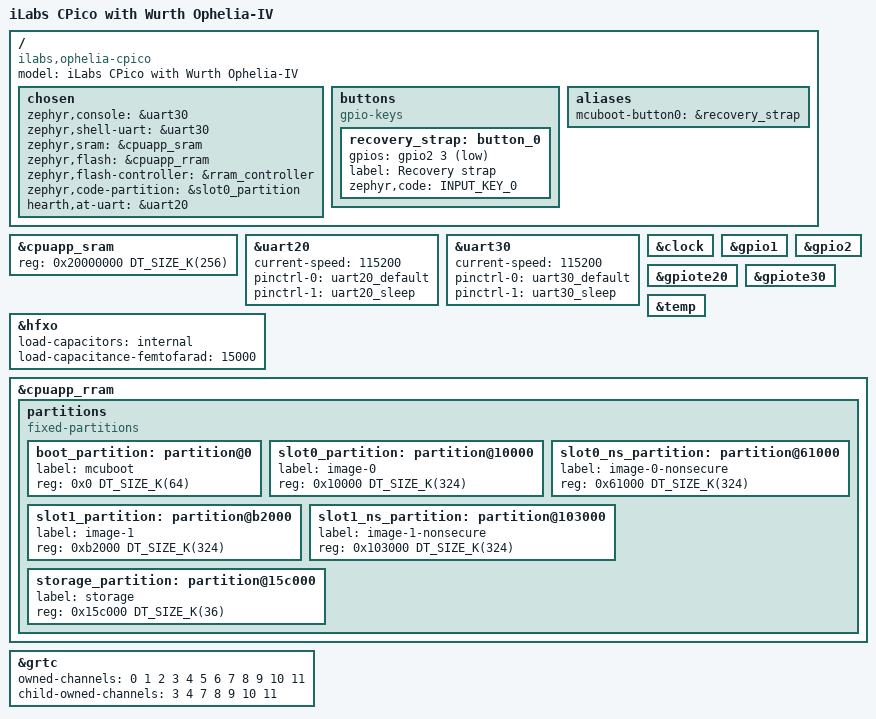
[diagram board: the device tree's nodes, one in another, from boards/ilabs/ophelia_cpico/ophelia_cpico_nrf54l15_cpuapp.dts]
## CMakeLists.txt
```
cmake_minimum_required(VERSION 3.20.0)
list(APPEND BOARD_ROOT ${CMAKE_CURRENT_LIST_DIR})
find_package(Zephyr REQUIRED HINTS $ENV{ZEPHYR_BASE})
project(hearth_nrf54l15)

# ---- the board contract (README.md, "Adding a board") -------------------
#
# A board on this platform has to name a UART twice, and it has to be the
# same UART both times:
#
#   the application's  hearth,at-uart      chosen node: where AT is spoken
#   MCUboot's          zephyr,uart-mcumgr  chosen node: where serial
#                                          recovery answers
#
# fw/flash.py drives ONE port and needs both of them. It straps the module
# into recovery, uploads the signed image over SMP, releases the strap and
# then waits for the application's +MTREADY, all on the same wire, because
# one wire is what a carrier brings out. A board whose two answers differ is
# not reflashable over that wire at all, and on a module whose SWD pads are a
# soldering job, that is a brick rather than an inconvenience.
#
# The two facts live in two images with two devicetrees, so no static_assert
# and no devicetree macro can see both. This checks the INPUT instead: it
# finds MCUboot's per-board overlay in this tree with the same zephyr_file()
# lookup MCUboot itself will use, reads the node label it names, and resolves
# that label against THIS image's devicetree. It catches the failure the
# round it was written for existed to remove (uart20 pinned unconditionally
# for every board, right on ophelia_cpico and the CONSOLE on both Nordic
# DKs, with nothing in the build saying so). It does not catch a
# -Dmcuboot_DTC_OVERLAY_FILE=... on the command line, which goes around the
# lookup entirely. That is the honest limit of a cross-image check here, and
# it is still worth having, because the version of this failure that has no
# check is silent until a board is on the bench.
string(REPLACE "/" "_" HEARTH_BOARD_FILE "${BOARD}${BOARD_QUALIFIERS}")

dt_chosen(HEARTH_AT_UART_NODE PROPERTY "hearth,at-uart")
if(NOT HEARTH_AT_UART_NODE)
  message(FATAL_ERROR
    "Board ${BOARD}${BOARD_QUALIFIERS} declares no `hearth,at-uart` chosen "
    "node, so nothing in this build says which UART carries the AT link.\n"
    "Add it to the board's devicetree, either a board directory under\n"
    "  ${CMAKE_CURRENT_LIST_DIR}/boards/<vendor>/<board>/\n"
    "for a board this repository defines, or an application overlay at\n"
    "  ${CMAKE_CURRENT_LIST_DIR}/boards/${HEARTH_BOARD_FILE}.overlay\n"
    "for an upstream board:\n"
    "  / { chosen { hearth,at-uart = &uartNN; }; };\n"
    "  &uartNN { status = \"okay\"; current-speed = <115200>; };\n"
    "There is deliberately no default. uart20 is the AT link on "
    "ophelia_cpico and is the CONSOLE on both Nordic DKs, so a default would "
    "be a coin toss that answers AT on the wrong pins without failing.\n"
    "See platform/nrf54l15/README.md, \"Adding a board\".")
endif()

if(CONFIG_BOOTLOADER_MCUBOOT)
  # The same two directories, in the same order, that MCUboot's own
  # DTC_OVERLAY_FILE discovery reads under its APPLICATION_CONFIG_DIR
  # (configuration_files.cmake:70-72: socs first, then boards), with the
  # SUFFIX every Zephyr-side lookup passes. Later entries win in devicetree
  # application order, and the loop below keeps the last match, so the two
  # agree about which file decides.
  set(HEARTH_MCUBOOT_IMAGE_DIR ${CMAKE_CURRENT_LIST_DIR}/sysbuild/mcuboot)
  set(HEARTH_MCUBOOT_BOARDS_DIR ${HEARTH_MCUBOOT_IMAGE_DIR}/boards)
  set(HEARTH_MCUBOOT_OVERLAYS)
  zephyr_file(CONF_FILES ${HEARTH_MCUBOOT_IMAGE_DIR}/socs DTS HEARTH_MCUBOOT_OVERLAYS
              QUALIFIERS SUFFIX ${FILE_SUFFIX})
  zephyr_file(CONF_FILES ${HEARTH_MCUBOOT_BOARDS_DIR} DTS HEARTH_MCUBOOT_OVERLAYS
              SUFFIX ${FILE_SUFFIX})

  set(HEARTH_MCUMGR_LABEL)
  set(HEARTH_MCUMGR_FILE)
  foreach(overlay ${HEARTH_MCUBOOT_OVERLAYS})
    file(READ ${overlay} hearth_overlay_text)
    # Comments come out first. CMake's MATCHES returns the FIRST match in the
    # string and these files are comment-heavy by house style, so a header
    # that quotes the property name in prose would otherwise steer the check
    # at whatever label the prose mentioned, and steer it SILENTLY, which is
    # the one failure class this whole check exists to remove.
    string(REGEX REPLACE "/\\*[^*]*\\*+([^/*][^*]*\\*+)*/" "" hearth_overlay_text
           "${hearth_overlay_text}")
    string(REGEX REPLACE "//[^\n]*" "" hearth_overlay_text "${hearth_overlay_text}")
    # `[^&]*` cannot cross the ampersand it is looking for, so this matches
    # the label of the first phandle after the property name and nothing
    # further. Whitespace and line breaks between the two are free. A value
    # written as a path phandle, &{/soc/uart@c6000}, matches nothing and
    # falls through to the "no zephyr,uart-mcumgr" error below, which still
    # points at the right file.
    if(hearth_overlay_text MATCHES "zephyr,uart-mcumgr[^&]*&([A-Za-z0-9_]+)")
      set(HEARTH_MCUMGR_LABEL ${CMAKE_MATCH_1})
      set(HEARTH_MCUMGR_FILE ${overlay})
    endif()
    unset(hearth_overlay_text)
  endforeach()

  if(NOT HEARTH_MCUMGR_LABEL)
    message(FATAL_ERROR
      "Board ${BOARD}${BOARD_QUALIFIERS} has no MCUboot serial-recovery UART.\n"
      "Nothing under\n"
      "  ${HEARTH_MCUBOOT_BOARDS_DIR}/\n"
      "sets `zephyr,uart-mcumgr` for this board; the file this build looks "
      "for is\n"
      "  ${HEARTH_MCUBOOT_BOARDS_DIR}/${HEARTH_BOARD_FILE}.overlay\n"
      "(a socs/ overlay for this SoC would do as well, and is read first)\n"
      "and it must name the same node as this board's `hearth,at-uart`, "
      "which is ${HEARTH_AT_UART_NODE}:\n"
      "  / { chosen { zephyr,uart-mcumgr = &uartNN; }; };\n"
      "  &uartNN { status = \"okay\"; };\n"
      "(Files found for this board: ${HEARTH_MCUBOOT_OVERLAYS})\n"
      "See platform/nrf54l15/README.md, \"Adding a board\".")
  endif()

  dt_nodelabel(HEARTH_MCUMGR_NODE NODELABEL "${HEARTH_MCUMGR_LABEL}")
  if(NOT HEARTH_MCUMGR_NODE)
    message(FATAL_ERROR
      "${HEARTH_MCUMGR_FILE}\n"
      "sets `zephyr,uart-mcumgr = &${HEARTH_MCUMGR_LABEL};`, but no node "
      "labelled ${HEARTH_MCUMGR_LABEL} exists in this board's devicetree. "
      "The two images share the board, so a label MCUboot can resolve is a "
      "label this image can resolve. Either the spelling is wrong, or the "
      "label is one the MCUboot overlay defines itself, which the AT link "
      "cannot be on: it has to be a node this image has too.")
  endif()

  if(NOT HEARTH_MCUMGR_NODE STREQUAL HEARTH_AT_UART_NODE)
    message(FATAL_ERROR
      "The AT link and MCUboot's serial recovery are on different UARTs on "
      "board ${BOARD}${BOARD_QUALIFIERS}, and fw/flash.py drives one port:\n"
      "  hearth,at-uart      ${HEARTH_AT_UART_NODE}\n"
      "  zephyr,uart-mcumgr  ${HEARTH_MCUMGR_NODE} (&${HEARTH_MCUMGR_LABEL})\n"
      "                      set in ${HEARTH_MCUMGR_FILE}\n"
      "Recovery would answer on a port the flasher never opens. Change "
      "whichever of the two is wrong for the hardware; on a carrier that "
      "brings out one UART, the AT link is the fixed point and recovery "
      "follows it.\n"
      "See platform/nrf54l15/README.md, \"Adding a board\".")
  endif()

  # ---- what the sysbuild/mcuboot/ directory costs, and its guard --------
  #
  # Creating that directory is what makes boards/<board>.overlay work for
  # the MCUboot image, and it is not free: sysbuild redirects the image's
  # APPLICATION_CONFIG_DIR to it (sysbuild_extensions.cmake, the
  # sysbuild_image_name_conf_dir branch), so Zephyr stops looking in
  # MCUboot's own bootloader/mcuboot/boot/zephyr for the image's
  # configuration inputs and looks here instead. Upstream ships three
  # Kconfig inputs at the paths that move:
  #
  #   prj.conf                    MCUboot's own base configuration
  #   socs/<soc>_<cluster>.conf   the per-SoC fragment
  #   boards/<board>.conf         a per-board fragment, if upstream has one
  #
  # Missing prj.conf fails the configure outright, which is at least loud.
  # A missing SoC fragment is SILENT: on the nRF54L15 it costs LTO,
  # ISR_TABLES_LOCAL_DECLARATION, the 512-byte RRAM write buffer
  # (NRF_RRAM_WRITE_BUFFER_SIZE counts 128-bit words, so 32 is 512 bytes and
  # the fallback 1 is 16) and BOOT_WATCHDOG_FEED=n, and the bootloader still
  # builds and still boots. So the two that exist for these SoCs are copied
  # under sysbuild/mcuboot/ (each file says so in its header) and this asks
  # upstream what it WOULD have contributed for the board being built, then
  # requires each answer to appear verbatim in the copy. An NCS bump that
  # edits one of them, and a new board whose SoC fragment nobody copied,
  # both fail here with the file to copy named. Same shape as the SDK patch
  # gate below: check the thing the build otherwise cannot see.
  #
  # THE REDIRECT MOVES THE DEVICETREE LOOKUPS TOO, and this guard does not
  # cover them, deliberately. Upstream also ships boot/zephyr/app.overlay,
  # boot/zephyr/boards/*.overlay and boot/zephyr/socs/*.overlay, and the
  # same APPLICATION_CONFIG_DIR redirect moves where those are looked for
  # (configuration_files.cmake:70-83). Nothing was lost there, because they
  # were already not applied before this round: sysbuild/mcuboot.overlay set
  # mcuboot_DTC_OVERLAY_FILE, which makes DTC_OVERLAY_FILE defined and skips
  # all three lookups outright. Demanding copies would therefore not restore
  # a lost setting, it would APPLY one for the first time: carrying
  # app.overlay would put zephyr,code-partition on &boot_partition where
  # this bootloader's devicetree has taken it from the board .dts since the
  # image existed, which Partition Manager overrides anyway. So the rule for
  # a new board is a reading task rather than a check: look in
  # bootloader/mcuboot/boot/zephyr/{boards,socs}/ for your target and fold
  # anything you need into your own per-board overlay by hand, because it
  # will not arrive on its own. README.md, "Adding a board", says so too.
  #
  # For the record on who does what upstream, because the first version of
  # this comment got it wrong: Nordic's Matter samples do NOT copy this
  # prj.conf. They author a bespoke, size-trimmed one and re-add LTO and
  # ISR_TABLES_LOCAL_DECLARATION in it and BOOT_WATCHDOG_FEED=n in their
  # per-board .conf, losing only NRF_RRAM_WRITE_BUFFER_SIZE. The copy-and-
  # carry-socs pattern used here is the one the SDK's own DFU samples use
  # (samples/dfu/compressed_update, samples/bluetooth/mesh/dfu/{target,
  # distributor}), so this is the SDK's other convention, not a departure
  # from it.
  if(NOT DEFINED ZEPHYR_MCUBOOT_MODULE_DIR)
    message(FATAL_ERROR
      "CONFIG_BOOTLOADER_MCUBOOT is set but the mcuboot Zephyr module is not "
      "in this workspace, so the bootloader image's configuration cannot be "
      "checked against upstream's.")
  endif()
  set(HEARTH_MCUBOOT_UPSTREAM_DIR ${ZEPHYR_MCUBOOT_MODULE_DIR}/boot/zephyr)
  set(HEARTH_MCUBOOT_LOCAL_DIR ${CMAKE_CURRENT_LIST_DIR}/sysbuild/mcuboot)

  # prj.conf is named rather than discovered, so unlike every other entry in
  # this list it is not known to exist. An upstream that ever drops it would
  # otherwise reach file(READ) and give a raw CMake error instead of this
  # block's own message.
  set(HEARTH_MCUBOOT_UPSTREAM_CONFS)
  if(EXISTS ${HEARTH_MCUBOOT_UPSTREAM_DIR}/prj.conf)
    list(APPEND HEARTH_MCUBOOT_UPSTREAM_CONFS ${HEARTH_MCUBOOT_UPSTREAM_DIR}/prj.conf)
  else()
    message(FATAL_ERROR
      "MCUboot no longer ships boot/zephyr/prj.conf, which this platform's "
      "sysbuild/mcuboot/prj.conf is a copy of:\n"
      "  looked for: ${HEARTH_MCUBOOT_UPSTREAM_DIR}/prj.conf\n"
      "Re-read how the MCUboot image gets its base configuration in this NCS "
      "before trusting the copy.")
  endif()
  zephyr_file(CONF_FILES ${HEARTH_MCUBOOT_UPSTREAM_DIR}/socs
              KCONF HEARTH_MCUBOOT_UPSTREAM_CONFS QUALIFIERS SUFFIX ${FILE_SUFFIX})
  zephyr_file(CONF_FILES ${HEARTH_MCUBOOT_UPSTREAM_DIR}/boards
              KCONF HEARTH_MCUBOOT_UPSTREAM_CONFS SUFFIX ${FILE_SUFFIX})

  # Containment, not equality, because the copies carry a header comment.
  # The consequence, stated here and in the copies: this sees upstream
  # changing, and does not see lines ADDED to a copy below the verbatim
  # block. Those apply silently and are the copies' one soft edge.
  foreach(upstream_conf ${HEARTH_MCUBOOT_UPSTREAM_CONFS})
    file(RELATIVE_PATH hearth_conf_rel ${HEARTH_MCUBOOT_UPSTREAM_DIR} ${upstream_conf})
    set(hearth_local_conf ${HEARTH_MCUBOOT_LOCAL_DIR}/${hearth_conf_rel})
    if(NOT EXISTS ${hearth_local_conf})
      message(FATAL_ERROR
        "MCUboot has a Kconfig fragment for board "
        "${BOARD}${BOARD_QUALIFIERS} that this platform does not carry, and "
        "the bootloader image will be built without it:\n"
        "  upstream: ${upstream_conf}\n"
        "  wanted:   ${hearth_local_conf}\n"
        "Copy it, under a header comment saying it is a copy and why (the "
        "files already there show the shape). It is not optional: the "
        "sysbuild/mcuboot/ directory that gives this image its per-board "
        "recovery-UART overlay also redirects where Zephyr looks for these, "
        "so what is not copied is simply not applied.")
    endif()
    file(READ ${upstream_conf} hearth_conf_upstream_text)
    file(READ ${hearth_local_conf} hearth_conf_local_text)
    string(FIND "${hearth_conf_local_text}" "${hearth_conf_upstream_text}"
           hearth_conf_found)
    if(hearth_conf_found EQUAL -1)
      message(FATAL_ERROR
        "MCUboot's own ${hearth_conf_rel} has changed and this platform's "
        "copy of it has not:\n"
        "  upstream: ${upstream_conf}\n"
        "  copy:     ${hearth_local_conf}\n"
        "Put upstream's current content back under the header comment in "
        "the copy, then rebuild the bootloader image and look at what "
        "moved.")
    endif()
    unset(hearth_conf_upstream_text)
    unset(hearth_conf_local_text)
  endforeach()
endif()

include(${CMAKE_CURRENT_LIST_DIR}/../../core/sources.cmake)

target_sources(app PRIVATE
    port/hearth_port_zephyr.c
    ${HEARTH_CORE_SOURCES})
target_include_directories(app PRIVATE ${HEARTH_CORE_INCLUDE_DIRS} port)
target_compile_definitions(app PRIVATE MT_COMBINED_IMAGE=0)

if(CONFIG_CHIP)
  # ---- the SDK patch gate (sdk-patches/README.md) -----------------------
  #
  # This platform carries patches against the pinned NCS workspace, and an
  # unpatched tree must not build quietly. Every patch here is deliberately
  # written to fall back to upstream behaviour when its macro is unset, which
  # is what makes it upstreamable, and is also exactly why a MISSING patch is
  # invisible: the build succeeds, the firmware works, and several kilobytes
  # of RAM come back without a word. That is the trap this check closes, and
  # the reason it is a hard error rather than a warning in a thousand-line
  # log. The remedy is one command and it is printed here.
  #
  # The marker is a REVISION, not a presence flag. Searching for the
  # configuration macro alone would pass on a workspace still carrying an
  # OLDER cut of the same patch: it would configure, build and measure
  # cleanly while running code nobody reviewed, which is the one failure a
  # presence check cannot see. Each patch therefore defines
  # HEARTH_<name>_PATCH_REV and this gate matches the number this tree
  # expects. Bump both together whenever a patch is re-cut.
  set(HEARTH_SDK_PATCH_DIR ${CMAKE_CURRENT_LIST_DIR}/sdk-patches)
  set(HEARTH_EEM_PATCH_REV 2)
  file(READ
    ${ZEPHYR_CONNECTEDHOMEIP_MODULE_DIR}/src/app/clusters/electrical-energy-measurement-server/ElectricalEnergyMeasurementCluster.cpp
    hearth_eem_src)
  string(FIND "${hearth_eem_src}"
    "HEARTH_EEM_POOL_PATCH_REV ${HEARTH_EEM_PATCH_REV}" hearth_eem_patched)
  string(FIND "${hearth_eem_src}" "HEARTH_EEM_POOL_PATCH_REV" hearth_eem_any_rev)
  unset(hearth_eem_src)
  if(hearth_eem_patched EQUAL -1)
    if(hearth_eem_any_rev EQUAL -1)
      set(hearth_eem_state "is NOT patched")
    else()
      set(hearth_eem_state "carries a DIFFERENT revision of the patch than revision ${HEARTH_EEM_PATCH_REV}, which this tree expects")
    endif()
    message(FATAL_ERROR
      "The Matter module at ${ZEPHYR_CONNECTEDHOMEIP_MODULE_DIR} ${hearth_eem_state}.\n"
      "This platform's memory figures and its EEM capacity both assume the patches in\n"
      "  ${HEARTH_SDK_PATCH_DIR}\n"
      "Apply them from the west workspace (run the clean first only if the tree is\n"
      "already patched at another revision):\n"
      "  cd ${ZEPHYR_BASE}/.. \\\n"
      "    && west patch -l ${HEARTH_SDK_PATCH_DIR}/patches.yml \\\n"
      "                  -b ${HEARTH_SDK_PATCH_DIR} clean \\\n"
      "    && west patch -l ${HEARTH_SDK_PATCH_DIR}/patches.yml \\\n"
      "                  -b ${HEARTH_SDK_PATCH_DIR} apply\n"
      "then build again.\n"
      "README.md in that directory says what each patch does, how to tell whether\n"
      "a tree is patched, and how to take it back out.")
  endif()

  include(${ZEPHYR_CONNECTEDHOMEIP_MODULE_DIR}/config/nrfconnect/app/enable-gnu-std.cmake)
  include(${ZEPHYR_CONNECTEDHOMEIP_MODULE_DIR}/src/app/chip_data_model.cmake)
  target_include_directories(matter-data-model PUBLIC ${CMAKE_CURRENT_SOURCE_DIR}/src/default_zap)
  chip_configure_data_model(matter-data-model
    BYPASS_IDL
    GEN_DIR ${CMAKE_CURRENT_SOURCE_DIR}/src/default_zap/zap-generated
    ZAP_FILE ${CMAKE_CURRENT_SOURCE_DIR}/src/default_zap/hearth.zap)

  set(MATTER_COMMON ${ZEPHYR_NRF_MODULE_DIR}/samples/matter/common/src)
  # src/default_zap is the ZAP_FILE's parent dir (chip_configure_data_model
  # above put the codegen output at src/default_zap/zap-generated): app's own
  # sources (main.cpp, matter_init.cpp) include <zap-generated/gen_config.h>
  # via app/util/attribute-storage.h, and that codegen dir was only ever added
  # to the matter-data-model target's own include path, not app's; mirrors
  # ZAP_PARENT_DIR in the template sample's CMakeLists.txt.
  # ../chip is the +MTEVT mapping shared with the MGM240P arm
  # (platform/chip/mt_chip_events.{h,cpp}). It sits outside this platform
  # directory on purpose: it names stock CHIP symbols only, so both Thread
  # ports compile the same file and the two arms cannot drift apart. It is
  # inside the CONFIG_CHIP guard because that is the only configuration in
  # which those symbols exist.
  target_include_directories(app PRIVATE src src/default_zap ../chip ${MATTER_COMMON}
    ${CMAKE_CURRENT_LIST_DIR}/../common)
  target_sources(app PRIVATE
    src/main.cpp
    ../chip/mt_chip_events.cpp
    port/mt_matter_stub.c
    port/hearth_ota_nrf.cpp
    ${CMAKE_CURRENT_LIST_DIR}/../common/hearth_ota_requestor.cpp
    port/mt_matter_zephyr.cpp
    port/mt_devtypes_zephyr.cpp
    ${MATTER_COMMON}/app/matter_init.cpp
    ${MATTER_COMMON}/app/matter_event_handler.cpp
    ${MATTER_COMMON}/app/task_executor.cpp
    ${MATTER_COMMON}/clusters/cluster_init.cpp)
  zephyr_linker_sources(SECTIONS ${MATTER_COMMON}/clusters/cluster_init.ld)
endif()
```

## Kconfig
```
#
# Without this file, Zephyr auto-generates a trivial app Kconfig root
# (mainmenu + source "Kconfig.zephyr") and nothing else. That default
# never reaches the CHIP module's own Kconfig.features/Kconfig.defaults
# fragments (they are not rsourced from chip-module/Kconfig itself, only
# from each sample's own top-level Kconfig, mirrored here), so options
# such as CHIP_CRYPTO_PSA's "default y" never apply and CHIP falls back
# to the legacy mbedTLS crypto backend, which this nrf_security build
# does not expose (mbedtls_ecp_muladd, mbedtls_pkcs5_pbkdf2_hmac: no
# declaration, build fails). Sourcing these two fragments is what makes
# the PSA-backed crypto path (CHIPCryptoPALPSA.cpp) the one actually
# built.
#
# Sourcing alone is not the whole story: prj.conf sets
# CONFIG_CHIP_CRYPTO_PSA=y explicitly rather than trusting the default
# even with these fragments sourced, because chip-module/Kconfig.defaults
# wraps that "default y" inside its own "if CHIP ... endif # CHIP" body,
# and this build passed through a CONFIG_CHIP=n window (sysbuild forcing
# the app image off) where that body, default included, was not reachable
# at all. See prj.conf's comment next to CONFIG_CHIP_CRYPTO_PSA=y for the
# full history.
#
# The common/src/Kconfig fragment below is sourced for the same reason:
# matter_init.cpp (platform/nrf54l15/CMakeLists.txt, ${MATTER_COMMON})
# is built straight out of the NCS Matter common sample sources and
# reads its own NCS_SAMPLE_MATTER_* symbols (task queue sizing, the
# settings shell, test event triggers, and so on) that only exist once
# this fragment is sourced. Mirrors how
# ~/ncs/v3.3.4/nrf/samples/matter/template/Kconfig reaches the same
# file via ${ZEPHYR_NRF_MODULE_DIR}.
#
mainmenu "Hearth nRF54L15 Matter Platform"

# ---- one image, said out loud (the FOTA relay round) ---------------------
#
# Zephyr defines UPDATEABLE_IMAGE_NUMBER inside "if IMG_MANAGER"
# (zephyr/subsys/dfu/Kconfig:97), and IMG_MANAGER in turn depends on
# STREAM_FLASH, so with the DFU image manager off the symbol does not exist
# at all. CHIP's own nrfconnect/OTAImageProcessorImpl.cpp reads it
# (OTAImageProcessorImpl.cpp:97) and the gn build compiles that file
# whenever chip_enable_ota_requestor is set, whether or not anything
# instantiates it (src/platform/nrfconnect/BUILD.gn:133). Turning the
# requestor on for the FOTA relay therefore stops the build in a file this
# firmware never links, on a symbol that only a subsystem it does not use
# would have defined.
#
# The alternative was to let IMG_MANAGER stand at the y CHIP_OTA_REQUESTOR
# implies, and it does not work here: IMG_MANAGER's only image-manager
# choice selects MCUBOOT_BOOTUTIL_LIB, whose bootutil_public.c is compiled
# in THIS image's Kconfig namespace, where CONFIG_SINGLE_APPLICATION_SLOT is
# an MCUboot-image symbol and therefore unset, so pm_sysflash.h takes its
# two-slot branch and the build fails on PM_MCUBOOT_SECONDARY_ID. The same
# single-slot partition map fails dfu_target_mcuboot.c on
# PM_MCUBOOT_SECONDARY_SIZE and PM_MCUBOOT_SECONDARY_ADDRESS. Both were
# tried; prj.conf's OTA block records the order.
#
# So the number is stated here instead, and it is not a workaround value:
# this device has exactly one updateable image, which is the whole premise
# of the host-driven update path (FIRMWARE_UPDATE_SPEC). It matches the
# default Zephyr would have given under IMG_MANAGER, and the only code that
# reads it in this build is the unreferenced file above.
config UPDATEABLE_IMAGE_NUMBER
	int
	default 1

source "$(ZEPHYR_CONNECTEDHOMEIP_MODULE_DIR)/config/nrfconnect/chip-module/Kconfig.features"
source "$(ZEPHYR_CONNECTEDHOMEIP_MODULE_DIR)/config/nrfconnect/chip-module/Kconfig.defaults"
source "$(ZEPHYR_NRF_MODULE_DIR)/samples/matter/common/src/Kconfig"
source "Kconfig.zephyr"
```

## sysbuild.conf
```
SB_CONFIG_BOOTLOADER_MCUBOOT=y
SB_CONFIG_MCUBOOT_MODE_SINGLE_APP=y
SB_CONFIG_BOOT_SIGNATURE_TYPE_ECDSA_P256=y
SB_CONFIG_BOOT_SIGNATURE_KEY_FILE="${APP_DIR}/keys/hearth_dev_p256.pem"

# Sysbuild gates CONFIG_CHIP on this: nrf/sysbuild/CMakeLists.txt forces
# CONFIG_CHIP=n on the app image unless SB_CONFIG_MATTER=y here, no matter
# what prj.conf says. SB_CONFIG_MATTER_OTA forces CONFIG_CHIP_OTA_REQUESTOR
# BOTH WAYS on the app image (sysbuild/CMakeLists.txt:832-837, a
# set_config_bool y in one branch and n in the other), so prj.conf's
# CONFIG_CHIP_OTA_REQUESTOR=y is only what it says while this is y. The FOTA
# relay needs the requestor, so it is y.
#
# This does NOT turn the app into a self-flashing device and it does not
# touch the bootloader mode: single-app MCUboot below stays, and the DFU
# machinery the requestor implies is switched off in prj.conf. What
# SB_CONFIG_MATTER_OTA additionally brings is CONFIG_CHIP_OTA_IMAGE_BUILD on
# the app image, a build step that wraps the signed application in a Matter
# OTA image header. That artifact is a by-product here: the bundle a host
# serves to this device is the host's business, not this build's.
SB_CONFIG_MATTER=y
SB_CONFIG_MATTER_OTA=y
```

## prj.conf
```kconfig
CONFIG_SERIAL=y
CONFIG_UART_USE_RUNTIME_CONFIGURE=y
# hearth_link_read (hearth_port_zephyr.c) drains the AT UART through the
# nrfx UARTE interrupt-driven API into a ring buffer, not uart_poll_in:
# this driver only stages a single RX byte at a time (re-armed per byte
# inside uart_fifo_read), and a poll loop with a k_msleep between polls
# loses bytes arriving during the sleep.
CONFIG_UART_INTERRUPT_DRIVEN=y
CONFIG_RING_BUFFER=y
CONFIG_LOG=y
CONFIG_REBOOT=y
CONFIG_MAIN_STACK_SIZE=4096
CONFIG_HEAP_MEM_POOL_SIZE=16384
CONFIG_DYNAMIC_THREAD=y
CONFIG_DYNAMIC_THREAD_ALLOC=y
CONFIG_DYNAMIC_THREAD_POOL_SIZE=2

# Persistent KV (hearth_kv_*, platform/nrf54l15/port/hearth_port_zephyr.c):
# settings over the ZMS backend, on the settings_storage partition.
CONFIG_FLASH=y
CONFIG_FLASH_MAP=y
CONFIG_ZMS=y
CONFIG_SETTINGS=y
CONFIG_SETTINGS_ZMS=y
# Memory reclaim round A. CHIP's own Kconfig.defaults sets this to 512
# (chip-module/Kconfig.defaults:91-92) against a Zephyr default of 128, and
# every entry costs 8 bytes of RAM (zephyr/include/zephyr/fs/zms.h:66), so
# 512 buckets is 4,096 B. The settings_storage partition is 32 KB and holds
# the heartbeat KV store plus Matter persistence: a bounded, modest key
# count, nothing like the hundreds a 512-bucket table implies.
#
# What a smaller cache actually costs (fix round M5, corrected: it is not
# what a "miss" costs). A slot holding ZMS_LOOKUP_CACHE_NO_ADDR makes
# zms_read_hist() answer -ENOENT immediately with no scan at all
# (zms.c:1757-1761), which is correct because an empty slot proves no id
# hashing to it was ever written. The cost is a COLLISION: a slot holds the
# newest ATE address among all ids hashing to it, and zms_find_ate_with_id()
# then walks backwards from there. That backwards walk is also what keeps a
# smaller cache correct: every colliding id's latest ATE stays reachable
# however many ids share a slot, so a collision costs scan length and never
# a failure or a lost write (zms.c:120, :145, :175-178, :294, :428, :1090,
# :1160, :1476-1487, :1609, :1757), on a boot path that is not
# latency-sensitive.
#
# CONFIG_ZMS_LOOKUP_CACHE_FOR_SETTINGS=y here (CHIP's chip-module/Kconfig:25
# implies it for SOC_FLASH_NRF_RRAM), and that hash reserves its low two bits
# for the name/data and linked-list discriminators, so `% 64` leaves four
# bits of settings-key discrimination, sixteen distinguishable keys, against
# seven bits and 128 at a cache size of 512. That is the number a bench
# observation of settings-read latency should be measured against.
CONFIG_ZMS_LOOKUP_CACHE_SIZE=64

# Matter core (spec section 7). CHIP's Kconfig.defaults pulls in BT,
# OpenThread, and the ZMS settings backend for this SoC on its own.
CONFIG_CHIP=y
CONFIG_STD_CPP17=y
CONFIG_CHIP_PROJECT_CONFIG="src/chip_project_config.h"
# Dev credentials this round: test DAC/VID/PID from SDK defaults, no
# factory data partition content (spec section 6).
CONFIG_CHIP_FACTORY_DATA_NONE=y
# The Matter OTA requestor is on, for the FOTA relay (docs:
# 2026-09-07-fota-design). The requestor downloads and the HOST stores and
# flashes: the co-processor has no second slot and never writes its own image
# (FIRMWARE_UPDATE_SPEC stays the update story, this only changes where the
# bundle comes from). So the single MCUboot slot stays, none of the DFU
# machinery NCS implies below is wanted, and NCS's own ota_util.cpp is not in
# CMakeLists.txt: the port defines InitBasicOTARequestor() and
# OtaConfirmNewImage() itself, in port/hearth_ota_nrf.cpp.
CONFIG_CHIP_OTA_REQUESTOR=y
# Nothing reboots on apply here. The host is told over AT (+MTOTA:APPLY) and
# reboots the co-processor itself when it has flashed the bundle.
CONFIG_CHIP_OTA_REQUESTOR_REBOOT_ON_APPLY=n
# CHIP_OTA_REQUESTOR implies SIX symbols (chip-module/Kconfig:90-97):
# DFU_MULTI_IMAGE, DFU_TARGET, BOOTLOADER_MCUBOOT, IMG_MANAGER, STREAM_FLASH
# and STREAM_FLASH_ERASE. The four written down here are turned off, because
# an imply loses to an explicit assignment and these four exist to write a
# downloaded image into an MCUboot secondary slot; this partition map has
# none, and the host is the image store.
#
# The other two are left alone, deliberately:
#   BOOTLOADER_MCUBOOT stands at y and is wanted. This platform boots through
#     MCUboot whatever Matter thinks, and sysbuild sets it on the app image
#     anyway. It is not free of consequence: it is what makes a --no-sysbuild
#     build link into slot0_partition instead of the whole RRAM, which is why
#     the DK core-sanity build now has to be a sysbuild one (README.md).
#   STREAM_FLASH_ERASE is not reachable at all here. It depends on
#     FLASH_HAS_EXPLICIT_ERASE, which this SoC's RRAM does not set, so the
#     symbol is absent from the generated .config rather than merely n. The code that would have used them, CHIP's own
# nrfconnect/OTAImageProcessorImpl.cpp, is compiled by the gn build whenever
# the requestor is on but is never instantiated, so its object file is not
# pulled out of libCHIP.a and none of these calls reach the link.
#
# Letting them stand at the implied y instead was tried first and does not
# build: IMG_MANAGER drags in mcuboot's bootutil_public.c and DFU_TARGET
# drags in dfu_target_mcuboot.c, both of which want a secondary slot
# (PM_MCUBOOT_SECONDARY_ID, PM_MCUBOOT_SECONDARY_ADDRESS) that a single-app
# partition map does not define. The one symbol OTAImageProcessorImpl.cpp
# genuinely needs, CONFIG_UPDATEABLE_IMAGE_NUMBER, is supplied by this
# platform's own Kconfig instead; the comment there has the whole story.
CONFIG_DFU_TARGET=n
CONFIG_DFU_MULTI_IMAGE=n
CONFIG_STREAM_FLASH=n
CONFIG_IMG_MANAGER=n
# NFC onboarding has no hardware here.
CONFIG_CHIP_NFC_ONBOARDING_PAYLOAD=n
CONFIG_BT_DEVICE_NAME="Hearth"
# An uncommissioned Hearth opens its commissioning window at boot and
# advertises. That is the product contract every other port already keeps
# (TESTING.md 2.1: "a fresh device opens a window automatically", which is
# what AT+MTSTATE? answering 1 and the boot +MTEVT:0 both mean), and it is
# what AT_MT_SPEC.md 3.11's boot event describes.
#
# It is written down HERE because this is the one platform where it is not
# the default. CHIP's CHIP_DEVICE_CONFIG_ENABLE_PAIRING_AUTOSTART is 1 on
# the ESP32 and EFR32 platforms, so the C6 and the MGM240P get it without
# asking; the nrfconnect platform binds it to this Kconfig and NCS leaves
# the Kconfig off (modules/lib/matter/src/platform/nrfconnect/
# CHIPDevicePlatformConfig.h:200-202). Nordic's own Matter samples and
# applications all set it back to y in their prj.conf, for the same reason.
#
# Without it Server::Init() opens no window on an uncommissioned boot, so
# AT+MTSTATE? answers 0 after AT+MTRESET, no +MTEVT:0 is ever raised at
# boot (mt_chip_events_after_ready()'s replay reads a closed window and
# emits nothing, correctly), and a controller has nothing to pair with
# until the host sends AT+MTCOMMISSION. Measured on the bench 2026-09-21,
# which is where it was found: harness Phase 2 cannot get past 2.3 on this
# port without it. See README "Events (+MTEVT)".
CONFIG_CHIP_ENABLE_PAIRING_AUTOSTART=y
# The CHIP_BOOTLOADER choice defaults to CHIP_BOOTLOADER_MCUBOOT on this
# SoC, which unconditionally selects IMG_MANAGER; that pulls in mcuboot's
# bootutil_public.c compiled against this image's own Kconfig namespace,
# where it expects a secondary (OTA) slot our single-slot partition map
# does not have. We do not need CHIP to know about the bootloader at all:
# the locked MCUboot install and serial recovery (platform/nrf54l15/README)
# are independent of Matter, and the requestor above hands every block to
# the host rather than to flash, so nothing here goes through CHIP's own
# image-management path.
CONFIG_CHIP_BOOTLOADER_NONE=y
# CHIP_CRYPTO_PSA defaults to y in the CHIP module's own Kconfig.defaults
# (sourced from platform/nrf54l15/Kconfig), but that "default y" sits
# inside the file's own "if CHIP ... endif # CHIP" body (chip-module/
# Kconfig.defaults:21-606, the default itself at :385-386). This build
# passed through a window where sysbuild forced the app image's own
# CONFIG_CHIP to n regardless of what this file asked for (see
# sysbuild.conf's SB_CONFIG_MATTER=y fix, same commit), and while that
# held, CHIP_CRYPTO_PSA's default never took hold: with CHIP=n the "if
# CHIP" body simply is not reachable, default included. Kept explicit
# here rather than trusted to the default even now that CHIP=y holds,
# since nothing about that history is worth re-litigating on every prj.conf
# read. Without it CHIP falls back to its legacy mbedTLS crypto backend,
# and this SoC's nrf_security build (CRACEN-first, PSA-only) does not
# expose the legacy mbedTLS API surface CHIP expects (mbedtls_ecp_muladd
# and similar go undeclared, fails to compile).
CONFIG_CHIP_CRYPTO_PSA=y

# Thread role and mesh sizing, memory reclaim round A.
#
# FTD is stated here rather than inherited. Until this round the build was
# a full Thread device only because OPENTHREAD_FTD is listed first in the
# Kconfig choice nobody set (zephyr/modules/openthread/Kconfig.thread:42-51),
# which made a 9 KB product decision look like an accident in every config
# dump. Ruling DE412: the router role is a KEPT product capability, the
# device must remain able to route, so the line is written down. MTD would
# return about 9,121 B of ot::Instance plus a 4 KB message-pool floor and
# is deliberately not taken.
CONFIG_OPENTHREAD_FTD=y
# 16 rather than the Zephyr default of 32 (Kconfig.thread:62-65), at 200 B
# of ot::Instance per child. Ruling DE412 fixed the number at 16 and NOT 8:
# the router role stays, and sixteen children is generous for a device of
# this kind. Only meaningful while FTD.
CONFIG_OPENTHREAD_MAX_CHILDREN=16

# WITHOUT THIS LINE THE DEVICE CANNOT ORIGINATE TRAFFIC OFF THE MESH, and
# the symptom names nothing: every outbound connection to anything past the
# border router simply never gets an answer.
#
# Zephyr's bridge to OpenThread's build is not a default, it is an
# assignment: kconfig_to_ot_option() forces OT_SLAAC=OFF when this symbol is
# unset (zephyr/modules/openthread/CMakeLists.txt:6-12 and :125), and
# OT_SLAAC is what defines OPENTHREAD_CONFIG_IP6_SLAAC_ENABLE. An unset
# symbol therefore compiles the SLAAC module OUT rather than leaving
# OpenThread's own default in place, and SLAAC is how a Thread device forms
# its address from the border router's OMR prefix, the one the network data
# advertises with the `a` flag. No SLAAC, no OMR address: the device holds
# only its RLOC, its mesh-local EID and a link-local address, all of which
# are unroutable off-mesh, so it has no legal source address for an
# off-mesh destination.
#
# Found on the bench in the FOTA round, and it had been true since this
# platform first spoke Thread. Nothing before this round had asked the
# device to START a conversation with anything outside the mesh: a
# commissioner reaches it at its mesh-local EID and the SRP server is
# on-mesh too, so every earlier bench row passed. The OTA requestor is the
# first outbound one, and it failed with the provider resolved, the address
# in hand and five CASE Sigma1 retransmissions unanswered (report:
# .superpowers/sdd/2026-09-07-fota-firmware/task-4-report.md).
CONFIG_OPENTHREAD_SLAAC=y

# The NCS Matter common Kconfig (platform/nrf54l15/Kconfig) declares this
# string symbol with no default; every NCS Matter sample's prj.conf sets it
# to its own ZAP file, so the value is set here too even though this
# platform's CMakeLists.txt passes the ZAP_FILE path to
# chip_configure_data_model() directly rather than through this symbol.
CONFIG_NCS_SAMPLE_MATTER_ZAP_FILE_PATH="${APPLICATION_CONFIG_DIR}/src/default_zap/hearth.zap"
```

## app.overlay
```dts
/* Board wiring (the AT link chosen, console, pin routing) now lives in
 * each board's own devicetree: platform/nrf54l15/boards/ilabs/ophelia_cpico/
 * for the target board, boards/nrf54l15dk_nrf54l15_cpuapp.overlay for the
 * Zephyr DK used during bring-up. This file stays for app-specific overlay
 * fragments that are not board wiring; it is currently empty.
 */
```

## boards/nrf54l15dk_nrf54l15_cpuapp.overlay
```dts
/* The AT link. On the DK this is the second VCOM (uart20 is the
 * console/shell UART, wired to zephyr,console in the board's own
 * dts); the Ophelia-IV board definition points it at the module's
 * host UART instead. uart21 IS a real SoC node (uart@c7000, disabled
 * by default, same as uart30), but the DK board's own pinctrl file
 * routes pins only for uart20 and uart30; uart21 has no board-level
 * pin routing to bring up, so uart30 stands in for the brief's uart21
 * placeholder.
 */
/ {
    chosen {
        hearth,at-uart = &uart30;
    };
};

&uart30 {
    status = "okay";
    current-speed = <115200>;
};

/* The SoC dtsi reserves 68 KB of the 256 KB physical SRAM for the
 * cpuflpr (VPR) coprocessor (nordic/nrf54l15.dtsi: cpuapp_sram defaults
 * to 188 KB); this core-sanity build never runs anything on cpuflpr.
 * Real CHIP server bring-up (Task 2, BT+OpenThread actually started)
 * overflows the default 188 KB region; reclaim the full 256 KB, same
 * as Nordic's own nrf54l15dk overlay in
 * nrf/samples/matter/template/boards/nrf54l15dk_nrf54l15_cpuapp.overlay
 * ("restore full RRAM and SRAM space").
 */
&cpuapp_sram {
    reg = <0x20000000 DT_SIZE_K(256)>;
    ranges = <0x0 0x20000000 DT_SIZE_K(256)>;
};
```

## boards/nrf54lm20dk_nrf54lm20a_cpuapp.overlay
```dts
/* The AT link on the nRF54LM20 DK. Same shape as the nRF54L15 DK overlay
 * next to this file: uart20 is the board's console/shell/mcumgr UART
 * (nrf54lm20_a_b_cpuapp_common.dtsi chooses it), so the AT link takes
 * uart30, the second VCOM, which the DK's own pinctrl already routes
 * (P0.06 TX, P0.07 RX, P0.08 RTS, P0.09 CTS in
 * nrf54lm20dk_nrf54lm20_a_b-pinctrl.dtsi). The board dtsi already gives
 * uart30 its pinctrl states and a 115200 default; only the chosen node
 * and the status are ours.
 *
 * WHAT THIS OVERLAY DELIBERATELY DOES NOT CARRY, since the nRF54L15
 * arms carry all three and copying them here would be wrong:
 *
 * - No `&cpuapp_sram` reclaim. On the nRF54L15 the SoC dtsi hands cpuapp
 *   only 188 KB of the 256 KB die and reserves the rest for the cpuflpr
 *   VPR, so both L15 boards reclaim it by hand. On this part
 *   nrf54lm20_a_b.dtsi already spans the whole 511 KB with cpuapp_sram
 *   and nrf54lm20_a_b_cpuapp.dtsi deletes cpuflpr_sram outright, so
 *   cpuapp owns 523,264 B with no overlay at all. Nordic's own Matter
 *   template overlay for this board has no &cpuapp_sram block either.
 *
 * - No `&hfxo` load-capacitor block. The Ophelia-IV needed one because
 *   its module carries no capacitor programming of its own, and the
 *   omission cost a bench session (radio silent, everything else
 *   healthy). This DK programs the identical 15,000 fF internal caps in
 *   nrf54lm20_a_b_cpuapp_common.dtsi, and 17,000 fF on the LFXO.
 *
 * - No LFCLK source guard. The Ophelia-IV has no 32 kHz crystal, so its
 *   board CMakeLists.txt fails the build if the RC source is not
 *   selected. This DK has an LFXO crystal and configures it; carrying
 *   the guard here would enforce the wrong choice on hardware that has
 *   the right one.
 *
 * The RRAM is also left at its 1940 KB default rather than reclaimed to
 * 2036 KB: the 96 KB tail belongs to the cpuflpr, nothing here runs on
 * it, and the partition map beside this file already leaves 52.9 percent
 * of the 1854 KB app slot unused (894,904 B used, measured 2026-08-31).
 * Reclaiming it is a decision for the round that needs the space.
 */
/ {
    chosen {
        hearth,at-uart = &uart30;
    };
};

&uart30 {
    status = "okay";
    current-speed = <115200>;
};
```

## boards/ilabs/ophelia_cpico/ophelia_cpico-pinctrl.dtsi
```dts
&pinctrl {
    uart20_default: uart20_default {
        group1 {
            psels = <NRF_PSEL(UART_TX, 1, 4)>,
                    <NRF_PSEL(UART_RX, 1, 15)>;
        };
    };
    uart20_sleep: uart20_sleep {
        group1 {
            psels = <NRF_PSEL(UART_TX, 1, 4)>,
                    <NRF_PSEL(UART_RX, 1, 15)>;
            low-power-enable;
        };
    };
    uart30_default: uart30_default {
        group1 {
            psels = <NRF_PSEL(UART_TX, 0, 0)>,
                    <NRF_PSEL(UART_RX, 0, 1)>;
        };
    };
    uart30_sleep: uart30_sleep {
        group1 {
            psels = <NRF_PSEL(UART_TX, 0, 0)>,
                    <NRF_PSEL(UART_RX, 0, 1)>;
            low-power-enable;
        };
    };
};
```

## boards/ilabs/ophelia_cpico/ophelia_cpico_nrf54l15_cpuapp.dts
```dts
/dts-v1/;
#include <nordic/nrf54l15_cpuapp.dtsi>
#include "ophelia_cpico-pinctrl.dtsi"

/ {
    model = "iLabs CPico with Wurth Ophelia-IV";
    compatible = "ilabs,ophelia-cpico";

    chosen {
        zephyr,console = &uart30;
        zephyr,shell-uart = &uart30;
        zephyr,sram = &cpuapp_sram;
        zephyr,flash = &cpuapp_rram;
        zephyr,flash-controller = &rram_controller;
        zephyr,code-partition = &slot0_partition;
        hearth,at-uart = &uart20;
    };

    buttons {
        compatible = "gpio-keys";
        recovery_strap: button_0 {
            gpios = <&gpio2 3 (GPIO_PULL_UP | GPIO_ACTIVE_LOW)>;
            label = "Recovery strap";
            zephyr,code = <INPUT_KEY_0>;
        };
    };

    aliases {
        mcuboot-button0 = &recovery_strap;
    };
};

/* The SoC dtsi reserves 68 KB of the 256 KB physical SRAM for the
 * cpuflpr (VPR) coprocessor (nordic/nrf54l15.dtsi: cpuapp_sram defaults
 * to 188 KB). This board never runs anything on cpuflpr (no VPR
 * firmware anywhere in this repo), so reclaim the full 256 KB for
 * cpuapp; matches the pattern in every Nordic nrf54l15dk board overlay
 * ("restore full RRAM and SRAM space"). Real CHIP server bring-up
 * (Task 2, PrepareServer/StartServer with BT+OpenThread actually
 * running) overflows the default 188 KB RAM region by ~15.3 KB; the
 * Task 1 skeleton never hit this because it never started the stack.
 */
&cpuapp_sram {
    reg = <0x20000000 DT_SIZE_K(256)>;
    ranges = <0x0 0x20000000 DT_SIZE_K(256)>;
    status = "okay";
};

&uart20 {
    status = "okay";
    current-speed = <115200>;
    pinctrl-0 = <&uart20_default>;
    pinctrl-1 = <&uart20_sleep>;
    pinctrl-names = "default", "sleep";
};

&uart30 {
    status = "okay";
    current-speed = <115200>;
    pinctrl-0 = <&uart30_default>;
    pinctrl-1 = <&uart30_sleep>;
    pinctrl-names = "default", "sleep";
};

/* The legacy nrf clock driver (CLOCK_CONTROL_NRF) needs this node; it
 * is what makes the K32SRC Kconfig choice visible, and the board
 * defconfig selects the internal RC there (no 32 kHz crystal on the
 * module). */
&clock { status = "okay"; };

/* The module's 32 MHz radio crystal uses the SoC's internal load
 * capacitors; without programming them the HFXO does not oscillate to
 * spec and the radio (BLE and 802.15.4 alike) transmits nothing while
 * every non-RF subsystem runs normally. Bench-found during the Matter
 * round: "CHIPoBLE advertising started" with no advertisement on the
 * air. Values from Zephyr's ophelia4ev board (same Ophelia-IV module). */
&hfxo {
    load-capacitors = "internal";
    load-capacitance-femtofarad = <15000>;
};

&gpio1 { status = "okay"; };
&gpio2 { status = "okay"; };
&gpiote20 { status = "okay"; };
&gpiote30 { status = "okay"; };

/* NRF_802154_SL (the 802.15.4 driver OpenThread/CHIP pull in) selects
 * TEMP_NRF5_MPSL for radio temperature compensation, which needs this
 * node enabled; disabled by default at the SoC dtsi level. Matches the
 * nrf54l15dk reference board. */
&temp { status = "okay"; };

&cpuapp_rram {
    partitions {
        compatible = "fixed-partitions";
        #address-cells = <1>;
        #size-cells = <1>;
        /* This fixed-partitions node is inert under sysbuild's Partition
         * Manager: pm_static.yml is the byte truth (48 KB mcuboot, 1342 KB
         * app). Kept only so bare non-sysbuild builds still link. */
        boot_partition: partition@0 {
            label = "mcuboot";
            reg = <0x0 DT_SIZE_K(64)>;
        };
        slot0_partition: partition@10000 {
            label = "image-0";
            reg = <0x10000 DT_SIZE_K(324)>;
        };
        slot0_ns_partition: partition@61000 {
            label = "image-0-nonsecure";
            reg = <0x61000 DT_SIZE_K(324)>;
        };
        slot1_partition: partition@b2000 {
            label = "image-1";
            reg = <0xb2000 DT_SIZE_K(324)>;
        };
        slot1_ns_partition: partition@103000 {
            label = "image-1-nonsecure";
            reg = <0x103000 DT_SIZE_K(324)>;
        };
        /* 32k from 0x154000 to 0x15bfff reserved for TF-M partitions */
        storage_partition: partition@15c000 {
            label = "storage";
            reg = <0x15c000 DT_SIZE_K(36)>;
        };
    };
};

/* The kernel timer. Without this the build silently falls back to a
 * SysTick configuration whose ISR never reaches the vector table, and
 * the first tick is a fatal spurious exception (found the hard way on
 * first boot). Channel split copied from the nrf54l15dk. */
&grtc {
    owned-channels = <0 1 2 3 4 5 6 7 8 9 10 11>;
    child-owned-channels = <3 4 7 8 9 10 11>;
    status = "okay";
};
```

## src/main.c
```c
/*
 * main.c - nRF54L15 skeleton entry point. Boot contract per the layout
 * spec section 5: bring up the (stubbed) Matter runtime, then
 * mt_at_start(), which emits +MTREADY.
 */

#include "mt_at.h"

int main(void)
{
    mt_at_start();
    return 0;
}
```

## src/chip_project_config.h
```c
/* chip_project_config.h - project-level CHIP configuration.
 *
 * 16 mirrors kServiceableEndpoints (port/mt_port_ids.h), the number of
 * endpoints this build can stand up and SERVE at once. It is deliberately
 * NOT MT_COMP_MAX_ENDPOINTS (core/include/mt_composition.h, 28), which is
 * how many a host may DECLARE over AT+MTEP: acceptance is a wire-contract
 * number both platforms share, capacity is what this 256 KB part affords.
 * See the long note on kServiceableEndpoints for the split, and the
 * README's "Endpoint capacity" section for what a host sees when a stored
 * composition is longer than capacity.
 *
 * This value sizes every compile-time per-endpoint pool inside CHIP, which
 * is most of what the reduction buys back: ColorControlServer's eleven
 * transition and quiet-reporting arrays, level-control's state table,
 * BooleanState's server pool, and the Thermostat / WindowCovering /
 * FanControl delegate tables.
 *
 * The literal is duplicated here rather than included because CHIP pulls
 * this header in everywhere, including C translation units, so it cannot
 * include the port's C++ headers. mt_devtypes_zephyr.cpp static_asserts
 * that the mirror has not drifted.
 */
#pragma once

#define CHIP_DEVICE_CONFIG_DYNAMIC_ENDPOINT_COUNT 16

/*
 * How many endpoints may carry ElectricalEnergyMeasurement AT ONCE.
 *
 * REQUIRES THE SDK PATCH in ../sdk-patches. Stock connectedhomeip does not
 * read this macro: it sizes its measurement table by the whole dynamic
 * endpoint space instead, 17 x 496 = 8,432 bytes charged the moment the
 * cluster enters the build, whether or not any composition declares an
 * energy endpoint. CMakeLists.txt refuses to configure against an unpatched
 * tree precisely so that this line cannot become a no-op nobody notices;
 * see sdk-patches/README.md.
 *
 * 8 is MT_MEAS_MAX (core/include/mt_matter.h), this port's own answer to
 * "how many measurement-capable endpoints may one composition carry", and
 * it is the only defensible number here. It was 4 for one round, chosen as
 * comfortably above any plausible composition, and that was an assertion
 * about plausibility rather than a bound: this port permits 16 dynamic
 * endpoints, six catalogue device types carry the cluster, and nothing
 * counted them. A composition this firmware ACCEPTS must be one it can
 * SERVE, so the pool is sized from the port's own capacity, and
 * mt_matter_zephyr.cpp static_asserts that the two cannot drift apart.
 *
 * Exhaustion is loud rather than silent: mt_matter_eem_reserve() claims a
 * slot before the endpoint is built and stops the composition rebuild
 * naming this macro, the way every other pool in this port does. Without
 * that gate a ninth EEM endpoint would apply cleanly and then answer
 * Failure to a controller reading its MANDATORY Accuracy attribute, with
 * nothing on the AT wire to say so. The gate is unreachable while every
 * EEM-bearing device type also declares ElectricalPowerMeasurement, which
 * exhausts the MT_MEAS_MAX EPM pool first; it is there for the seventh type
 * that does not.
 *
 * A slot is reclaimed automatically once its endpoint stops serving the
 * cluster, so this is a concurrency bound and not a lifetime budget.
 */
#define CHIP_CONFIG_ELECTRICAL_ENERGY_MEASUREMENT_MAX_INSTANCES 8
```
